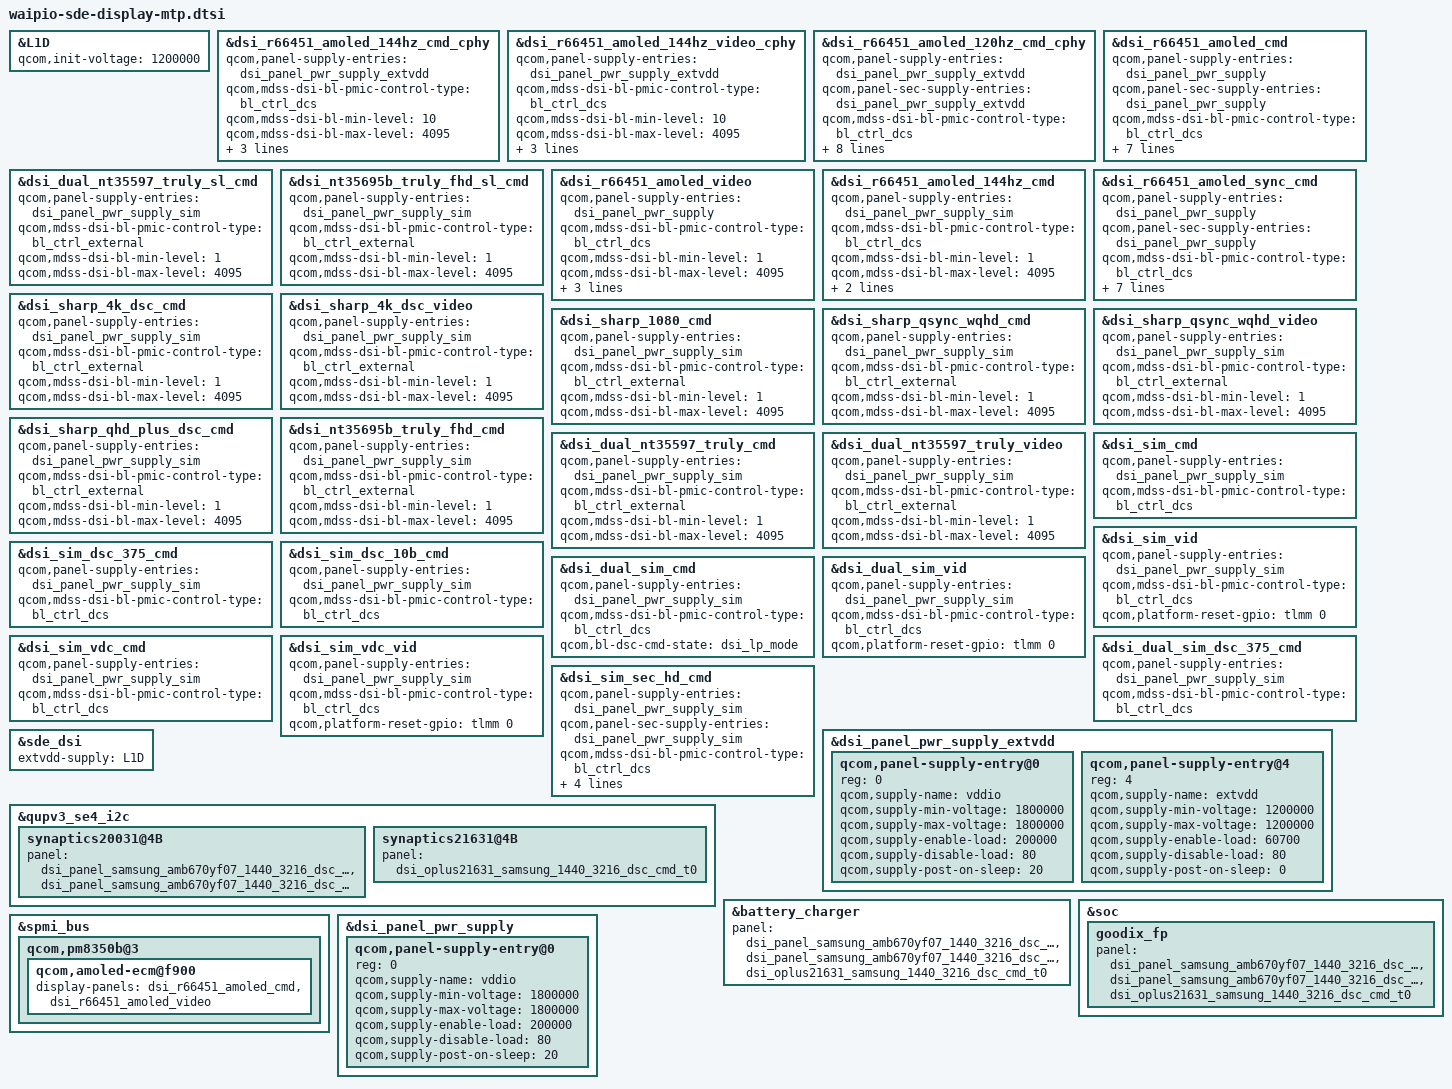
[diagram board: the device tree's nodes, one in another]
#include "waipio-sde-display.dtsi"

&L1D {
	qcom,init-voltage = <1200000>; /* panel ext vdd */
};

&dsi_r66451_amoled_144hz_cmd_cphy {
	qcom,panel-supply-entries = <&dsi_panel_pwr_supply_extvdd>;
	qcom,mdss-dsi-bl-pmic-control-type = "bl_ctrl_dcs";
	qcom,mdss-dsi-bl-min-level = <10>;
	qcom,mdss-dsi-bl-max-level = <4095>;
	qcom,mdss-brightness-max-level = <8191>;
	qcom,mdss-dsi-bl-inverted-dbv;
	qcom,platform-reset-gpio = <&tlmm 0 0>;
};

&dsi_r66451_amoled_144hz_video_cphy {
	qcom,panel-supply-entries = <&dsi_panel_pwr_supply_extvdd>;
	qcom,mdss-dsi-bl-pmic-control-type = "bl_ctrl_dcs";
	qcom,mdss-dsi-bl-min-level = <10>;
	qcom,mdss-dsi-bl-max-level = <4095>;
	qcom,mdss-brightness-max-level = <8191>;
	qcom,mdss-dsi-bl-inverted-dbv;
	qcom,platform-reset-gpio = <&tlmm 0 0>;
};

&dsi_r66451_amoled_120hz_cmd_cphy {
	qcom,panel-supply-entries = <&dsi_panel_pwr_supply_extvdd>;
	qcom,panel-sec-supply-entries = <&dsi_panel_pwr_supply_extvdd>;
	qcom,mdss-dsi-bl-pmic-control-type = "bl_ctrl_dcs";
	qcom,mdss-dsi-sec-bl-pmic-control-type = "bl_ctrl_dcs";
	qcom,mdss-dsi-bl-min-level = <10>;
	qcom,mdss-dsi-bl-max-level = <4095>;
	qcom,mdss-brightness-max-level = <8191>;
	qcom,mdss-dsi-bl-inverted-dbv;
	qcom,platform-reset-gpio = <&tlmm 0 0>;
	qcom,platform-sec-reset-gpio = <&tlmm 4 0>;
};

&dsi_r66451_amoled_cmd {
	qcom,panel-supply-entries = <&dsi_panel_pwr_supply>;
	qcom,panel-sec-supply-entries = <&dsi_panel_pwr_supply>;
	qcom,mdss-dsi-bl-pmic-control-type = "bl_ctrl_dcs";
	qcom,mdss-dsi-sec-bl-pmic-control-type = "bl_ctrl_dcs";
	qcom,mdss-dsi-bl-min-level = <1>;
	qcom,mdss-dsi-bl-max-level = <4095>;
	qcom,mdss-brightness-max-level = <8191>;
	qcom,mdss-dsi-bl-inverted-dbv;
	qcom,platform-reset-gpio = <&tlmm 0 0>;
};

&dsi_dual_nt35597_truly_sl_cmd {
	qcom,panel-supply-entries = <&dsi_panel_pwr_supply_sim>;
	qcom,mdss-dsi-bl-pmic-control-type = "bl_ctrl_external";
	qcom,mdss-dsi-bl-min-level = <1>;
	qcom,mdss-dsi-bl-max-level = <4095>;
};

&dsi_nt35695b_truly_fhd_sl_cmd {
	qcom,panel-supply-entries = <&dsi_panel_pwr_supply_sim>;
	qcom,mdss-dsi-bl-pmic-control-type = "bl_ctrl_external";
	qcom,mdss-dsi-bl-min-level = <1>;
	qcom,mdss-dsi-bl-max-level = <4095>;
};

&dsi_r66451_amoled_video {
	qcom,panel-supply-entries = <&dsi_panel_pwr_supply>;
	qcom,mdss-dsi-bl-pmic-control-type = "bl_ctrl_dcs";
	qcom,mdss-dsi-bl-min-level = <1>;
	qcom,mdss-dsi-bl-max-level = <4095>;
	qcom,mdss-brightness-max-level = <8191>;
	qcom,mdss-dsi-bl-inverted-dbv;
	qcom,platform-reset-gpio = <&tlmm 0 0>;
};

&dsi_r66451_amoled_144hz_cmd {
	qcom,panel-supply-entries = <&dsi_panel_pwr_supply_sim>;
	qcom,mdss-dsi-bl-pmic-control-type = "bl_ctrl_dcs";
	qcom,mdss-dsi-bl-min-level = <1>;
	qcom,mdss-dsi-bl-max-level = <4095>;
	qcom,mdss-brightness-max-level = <8191>;
	qcom,mdss-dsi-bl-inverted-dbv;
};

&dsi_r66451_amoled_sync_cmd {
	qcom,panel-supply-entries = <&dsi_panel_pwr_supply>;
	qcom,panel-sec-supply-entries = <&dsi_panel_pwr_supply>;
	qcom,mdss-dsi-bl-pmic-control-type = "bl_ctrl_dcs";
	qcom,mdss-dsi-sec-bl-pmic-control-type = "bl_ctrl_dcs";
	qcom,mdss-dsi-bl-min-level = <1>;
	qcom,mdss-dsi-bl-max-level = <4095>;
	qcom,mdss-brightness-max-level = <8191>;
	qcom,mdss-dsi-bl-inverted-dbv;
	qcom,platform-reset-gpio = <&tlmm 0 0>;
};

&dsi_sharp_4k_dsc_cmd {
	qcom,panel-supply-entries = <&dsi_panel_pwr_supply_sim>;
	qcom,mdss-dsi-bl-pmic-control-type = "bl_ctrl_external";
	qcom,mdss-dsi-bl-min-level = <1>;
	qcom,mdss-dsi-bl-max-level = <4095>;
};

&dsi_sharp_4k_dsc_video {
	qcom,panel-supply-entries = <&dsi_panel_pwr_supply_sim>;
	qcom,mdss-dsi-bl-pmic-control-type = "bl_ctrl_external";
	qcom,mdss-dsi-bl-min-level = <1>;
	qcom,mdss-dsi-bl-max-level = <4095>;
};

&dsi_sharp_1080_cmd {
	qcom,panel-supply-entries = <&dsi_panel_pwr_supply_sim>;
	qcom,mdss-dsi-bl-pmic-control-type = "bl_ctrl_external";
	qcom,mdss-dsi-bl-min-level = <1>;
	qcom,mdss-dsi-bl-max-level = <4095>;
};

&dsi_sharp_qsync_wqhd_cmd {
	qcom,panel-supply-entries = <&dsi_panel_pwr_supply_sim>;
	qcom,mdss-dsi-bl-pmic-control-type = "bl_ctrl_external";
	qcom,mdss-dsi-bl-min-level = <1>;
	qcom,mdss-dsi-bl-max-level = <4095>;
};

&dsi_sharp_qsync_wqhd_video {
	qcom,panel-supply-entries = <&dsi_panel_pwr_supply_sim>;
	qcom,mdss-dsi-bl-pmic-control-type = "bl_ctrl_external";
	qcom,mdss-dsi-bl-min-level = <1>;
	qcom,mdss-dsi-bl-max-level = <4095>;
};

&dsi_sharp_qhd_plus_dsc_cmd {
	qcom,panel-supply-entries = <&dsi_panel_pwr_supply_sim>;
	qcom,mdss-dsi-bl-pmic-control-type = "bl_ctrl_external";
	qcom,mdss-dsi-bl-min-level = <1>;
	qcom,mdss-dsi-bl-max-level = <4095>;
};

&dsi_nt35695b_truly_fhd_cmd {
	qcom,panel-supply-entries = <&dsi_panel_pwr_supply_sim>;
	qcom,mdss-dsi-bl-pmic-control-type = "bl_ctrl_external";
	qcom,mdss-dsi-bl-min-level = <1>;
	qcom,mdss-dsi-bl-max-level = <4095>;
};

&dsi_dual_nt35597_truly_cmd {
	qcom,panel-supply-entries = <&dsi_panel_pwr_supply_sim>;
	qcom,mdss-dsi-bl-pmic-control-type = "bl_ctrl_external";
	qcom,mdss-dsi-bl-min-level = <1>;
	qcom,mdss-dsi-bl-max-level = <4095>;
};

&dsi_dual_nt35597_truly_video {
	qcom,panel-supply-entries = <&dsi_panel_pwr_supply_sim>;
	qcom,mdss-dsi-bl-pmic-control-type = "bl_ctrl_external";
	qcom,mdss-dsi-bl-min-level = <1>;
	qcom,mdss-dsi-bl-max-level = <4095>;
};

&dsi_sim_cmd {
	qcom,panel-supply-entries = <&dsi_panel_pwr_supply_sim>;
	qcom,mdss-dsi-bl-pmic-control-type = "bl_ctrl_dcs";
};

&dsi_sim_vid {
	qcom,panel-supply-entries = <&dsi_panel_pwr_supply_sim>;
	qcom,mdss-dsi-bl-pmic-control-type = "bl_ctrl_dcs";
	qcom,platform-reset-gpio = <&tlmm 0 0>;
};

&dsi_sim_dsc_375_cmd {
	qcom,panel-supply-entries = <&dsi_panel_pwr_supply_sim>;
	qcom,mdss-dsi-bl-pmic-control-type = "bl_ctrl_dcs";
};

&dsi_sim_dsc_10b_cmd {
	qcom,panel-supply-entries = <&dsi_panel_pwr_supply_sim>;
	qcom,mdss-dsi-bl-pmic-control-type = "bl_ctrl_dcs";
};

&dsi_dual_sim_cmd {
	qcom,panel-supply-entries = <&dsi_panel_pwr_supply_sim>;
	qcom,mdss-dsi-bl-pmic-control-type = "bl_ctrl_dcs";
	qcom,bl-dsc-cmd-state = "dsi_lp_mode";
};

&dsi_dual_sim_vid {
	qcom,panel-supply-entries = <&dsi_panel_pwr_supply_sim>;
	qcom,mdss-dsi-bl-pmic-control-type = "bl_ctrl_dcs";
	qcom,platform-reset-gpio = <&tlmm 0 0>;
};

&dsi_sim_vdc_cmd {
	qcom,panel-supply-entries = <&dsi_panel_pwr_supply_sim>;
	qcom,mdss-dsi-bl-pmic-control-type = "bl_ctrl_dcs";
};

&dsi_sim_vdc_vid {
	qcom,panel-supply-entries = <&dsi_panel_pwr_supply_sim>;
	qcom,mdss-dsi-bl-pmic-control-type = "bl_ctrl_dcs";
	qcom,platform-reset-gpio = <&tlmm 0 0>;
};

&dsi_dual_sim_dsc_375_cmd {
	qcom,panel-supply-entries = <&dsi_panel_pwr_supply_sim>;
	qcom,mdss-dsi-bl-pmic-control-type = "bl_ctrl_dcs";
};

&dsi_sim_sec_hd_cmd {
	qcom,panel-supply-entries = <&dsi_panel_pwr_supply_sim>;
	qcom,panel-sec-supply-entries = <&dsi_panel_pwr_supply_sim>;
	qcom,mdss-dsi-bl-pmic-control-type = "bl_ctrl_dcs";
	qcom,mdss-dsi-sec-bl-pmic-control-type = "bl_ctrl_dcs";
	qcom,mdss-dsi-bl-min-level = <1>;
	qcom,mdss-dsi-bl-max-level = <1023>;
};

&dsi_panel_pwr_supply_extvdd {
	qcom,panel-supply-entry@0 {
		reg = <0>;
		qcom,supply-name = "vddio";
		qcom,supply-min-voltage = <1800000>;
		qcom,supply-max-voltage = <1800000>;
		qcom,supply-enable-load = <200000>;
		qcom,supply-disable-load = <80>;
		qcom,supply-post-on-sleep = <20>;
	};

	qcom,panel-supply-entry@4 {
		reg = <4>;
		qcom,supply-name = "extvdd";
		qcom,supply-min-voltage = <1200000>;
		qcom,supply-max-voltage = <1200000>;
		qcom,supply-enable-load = <60700>;
		qcom,supply-disable-load = <80>;
		qcom,supply-post-on-sleep = <0>;
	};
};

&sde_dsi {
	extvdd-supply = <&L1D>;
};

&qupv3_se4_i2c {
	synaptics20031@4B {
		panel = <&dsi_panel_samsung_amb670yf07_1440_3216_dsc_cmd
				&dsi_panel_samsung_amb670yf07_1440_3216_dsc_cmd_t0>;
	};
	synaptics21631@4B {
		panel = <&dsi_oplus21631_samsung_1440_3216_dsc_cmd_t0>;
	};
};

//#ifdef OPLUS_FEATURE_CHG_BASIC
&battery_charger {
	panel = <&dsi_panel_samsung_amb670yf07_1440_3216_dsc_cmd
				&dsi_panel_samsung_amb670yf07_1440_3216_dsc_cmd_t0
				&dsi_oplus21631_samsung_1440_3216_dsc_cmd_t0>;
};
//#endif

&soc {
	//#ifdef OPLUS_FEATURE_FINGERPRINT
	goodix_fp {
		panel = <&dsi_panel_samsung_amb670yf07_1440_3216_dsc_cmd &dsi_panel_samsung_amb670yf07_1440_3216_dsc_cmd_t0 &dsi_oplus21631_samsung_1440_3216_dsc_cmd_t0>;
	};
	//#endif /*OPLUS_FEATURE_FINGERPRINT*/
};

&spmi_bus {
	qcom,pm8350b@3 {
		qcom,amoled-ecm@f900 {
			display-panels = <&dsi_r66451_amoled_cmd
					&dsi_r66451_amoled_video>;
		};
	};
};

&dsi_panel_pwr_supply {
		qcom,panel-supply-entry@0 {
			reg = <0>;
			qcom,supply-name = "vddio";
			qcom,supply-min-voltage = <1800000>;
			qcom,supply-max-voltage = <1800000>;
			qcom,supply-enable-load = <200000>;
			qcom,supply-disable-load = <80>;
			qcom,supply-post-on-sleep = <20>;
		};
};
